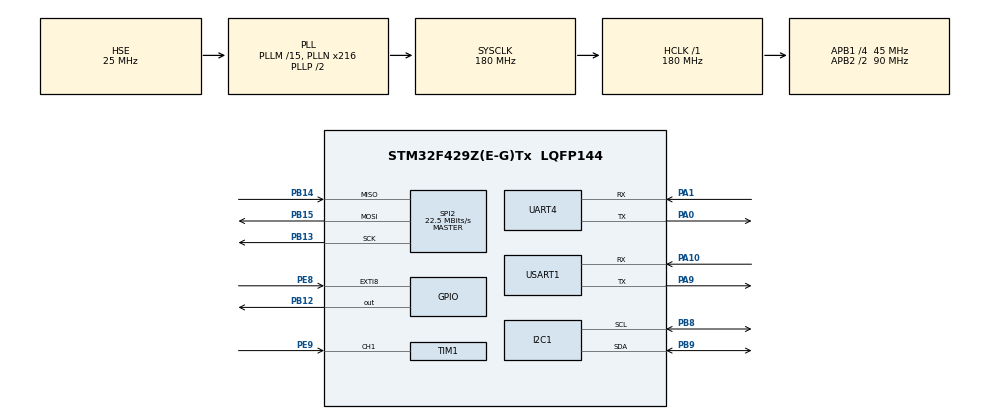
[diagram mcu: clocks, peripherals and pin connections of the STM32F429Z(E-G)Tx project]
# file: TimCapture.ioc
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I2C1.I2C_Mode=I2C_Fast
Mcu.Family=STM32F4
Mcu.Name=STM32F429Z(E-G)Tx
Mcu.Package=LQFP144
NVIC.EXTI9_5_IRQn=true\:0\:0\:false\:false\:true\:true\:true\:true
NVIC.PriorityGroup=NVIC_PRIORITYGROUP_4
NVIC.TIM1_CC_IRQn=true\:0\:0\:false\:false\:true\:true\:true\:true
NVIC.TIM1_UP_TIM10_IRQn=true\:0\:0\:false\:false\:true\:true\:true\:true
NVIC.TIM6_DAC_IRQn=true\:2\:0\:true\:false\:true\:true\:true\:true
NVIC.UART4_IRQn=true\:1\:0\:true\:false\:true\:true\:true\:true
NVIC.USART1_IRQn=true\:1\:0\:true\:false\:true\:true\:true\:true
PA0/WKUP.Mode=Asynchronous
PA0/WKUP.Signal=UART4_TX
PA1.Mode=Asynchronous
PA1.Signal=UART4_RX
PA10.Mode=Asynchronous
PA10.Signal=USART1_RX
PA13.Mode=Serial_Wire
PA13.Signal=SYS_JTMS-SWDIO
PA14.Mode=Serial_Wire
PA14.Signal=SYS_JTCK-SWCLK
PA9.Mode=Asynchronous
PA9.Signal=USART1_TX
PB12.GPIO_Speed=GPIO_SPEED_FREQ_HIGH
PB12.PinState=GPIO_PIN_SET
PB12.Signal=GPIO_Output
PB13.Mode=Full_Duplex_Master
PB13.Signal=SPI2_SCK
PB14.Mode=Full_Duplex_Master
PB14.Signal=SPI2_MISO
PB15.Mode=Full_Duplex_Master
PB15.Signal=SPI2_MOSI
PB8.Mode=I2C
PB8.Signal=I2C1_SCL
PB9.Mode=I2C
PB9.Signal=I2C1_SDA
PE8.GPIO_ModeDefaultEXTI=GPIO_MODE_IT_FALLING
PE8.GPIO_PuPd=GPIO_PULLUP
PE8.Signal=GPXTI8
PE9.Signal=S_TIM1_CH1
PH0/OSC_IN.Mode=HSE-External-Oscillator
PH0/OSC_IN.Signal=RCC_OSC_IN
PH1/OSC_OUT.Mode=HSE-External-Oscillator
PH1/OSC_OUT.Signal=RCC_OSC_OUT
ProjectManager.HeapSize=0x200
ProjectManager.StackSize=0x400
ProjectManager.TargetToolchain=MDK-ARM V5.32
RCC.48MHZClocksFreq_Value=90000000
RCC.AHBFreq_Value=180000000
RCC.APB1CLKDivider=RCC_HCLK_DIV4
RCC.APB1Freq_Value=45000000
RCC.APB1TimFreq_Value=90000000
RCC.APB2CLKDivider=RCC_HCLK_DIV2
RCC.APB2Freq_Value=90000000
RCC.APB2TimFreq_Value=180000000
RCC.CortexFreq_Value=180000000
RCC.HCLKFreq_Value=180000000
RCC.HSE_VALUE=25000000
RCC.HSI_VALUE=16000000
RCC.LSE_VALUE=32768
RCC.PLLM=15
RCC.PLLN=216
RCC.PLLSourceVirtual=RCC_PLLSOURCE_HSE
RCC.SYSCLKFreq_VALUE=180000000
RCC.SYSCLKSource=RCC_SYSCLKSOURCE_PLLCLK
RCC.VCOOutputFreq_Value=360000000
SH.S_TIM1_CH1.0=TIM1_CH1,Input_Capture1_from_TI1
SPI2.CalculateBaudRate=22.5 MBits/s
SPI2.Direction=SPI_DIRECTION_2LINES
SPI2.Mode=SPI_MODE_MASTER
SPI2.VirtualType=VM_MASTER
TIM1.AutoReloadPreload=TIM_AUTORELOAD_PRELOAD_ENABLE
TIM1.Channel-Input_Capture1_from_TI1=TIM_CHANNEL_1
TIM1.Channel-Input_Capture2_from_TI1_63=TIM_CHANNEL_2
TIM1.ICFilter_CH1=8
TIM1.ICPolarity_CH1=TIM_INPUTCHANNELPOLARITY_FALLING
TIM1.ICPrescaler-Input_Capture1_from_TI1=TIM_ICPSC_DIV1
TIM1.ICPrescaler-Input_Capture2_from_TI1_63=TIM_ICPSC_DIV1
TIM1.Period=1000-1
TIM1.Prescaler=180-1
TIM1.TIM_MasterOutputTrigger=TIM_TRGO_UPDATE
TIM6.Period=1000-1
TIM6.Prescaler=90-1
TIM6.TIM_MasterOutputTrigger=TIM_TRGO_UPDATE
UART4.VirtualMode=Asynchronous
USART1.VirtualMode=VM_ASYNC
VP_TIM1_VS_ClockSourceINT.Mode=Internal
VP_TIM1_VS_indirect_ch1.Mode=Input_Capture2_from_TI1_63
VP_TIM6_VS_ClockSourceINT.Mode=Enable_Timer
board=custom

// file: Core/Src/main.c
/* USER CODE BEGIN Header */
/**
  ******************************************************************************
  * @file           : main.c
  * @brief          : Main program body
  ******************************************************************************
  * @attention
  *
  * Copyright (c) 2025 STMicroelectronics.
  * All rights reserved.
  *
  * This software is licensed under terms that can be found in the LICENSE file
  * in the root directory of this software component.
  * If no LICENSE file comes with this software, it is provided AS-IS.
  *
  ******************************************************************************
  */
/* USER CODE END Header */
#include "main.h"
#include "i2c.h"
#include "spi.h"
#include "tim.h"
#include "usart.h"
#include "gpio.h"

/* USER CODE BEGIN Includes */
#include "stdio.h"
#include "oled.h"
#include "TimCapture.h"
#include "GD25Q40E.h"
#include "OTA_UpdateCheck.h"
/* USER CODE END Includes */

void SystemClock_Config(void);

int main(void)
{

  /* USER CODE BEGIN 1 */
	SCB->VTOR = FLASH_BASE | 0xC000;
  /* USER CODE END 1 */

  /* MCU Configuration--------------------------------------------------------*/

  /* Reset of all peripherals, Initializes the Flash interface and the Systick. */
  HAL_Init();

  /* Configure the system clock */
  SystemClock_Config();

  /* Initialize all configured peripherals */
  MX_GPIO_Init();
  MX_I2C1_Init();
  MX_TIM1_Init();
  MX_SPI2_Init();
  MX_TIM6_Init();
  MX_USART1_UART_Init();
  MX_UART4_Init();
  /* USER CODE BEGIN 2 */
	GD25Q40E_Init(&hgd1,GPIOB,GPIO_PIN_12,&hspi2);
	tim1_init();
	OLED_Init();

  /* USER CODE END 2 */

  /* Infinite loop */
  /* USER CODE BEGIN WHILE */
	char info[50] = {0};
  while (1)
  {
    /* USER CODE END WHILE */

    /* USER CODE BEGIN 3 */

		sprintf(info,"click:%d", \
		Key_Event.click);
		OLED_ShowStr(0,1,info,8);
		OTA_UpdateCheck(&OTA_Info);
  }
  /* USER CODE END 3 */
}

void SystemClock_Config(void)
{
  RCC_OscInitTypeDef RCC_OscInitStruct = {0};
  RCC_ClkInitTypeDef RCC_ClkInitStruct = {0};

  /** Configure the main internal regulator output voltage
  */
  __HAL_RCC_PWR_CLK_ENABLE();
  __HAL_PWR_VOLTAGESCALING_CONFIG(PWR_REGULATOR_VOLTAGE_SCALE1);

  /** Initializes the RCC Oscillators according to the specified parameters
  * in the RCC_OscInitTypeDef structure.
  */
  RCC_OscInitStruct.OscillatorType = RCC_OSCILLATORTYPE_HSE;
  RCC_OscInitStruct.HSEState = RCC_HSE_ON;
  RCC_OscInitStruct.PLL.PLLState = RCC_PLL_ON;
  RCC_OscInitStruct.PLL.PLLSource = RCC_PLLSOURCE_HSE;
  RCC_OscInitStruct.PLL.PLLM = 15;
  RCC_OscInitStruct.PLL.PLLN = 216;
  RCC_OscInitStruct.PLL.PLLP = RCC_PLLP_DIV2;
  RCC_OscInitStruct.PLL.PLLQ = 4;
  if (HAL_RCC_OscConfig(&RCC_OscInitStruct) != HAL_OK)
  {
    Error_Handler();
  }

  /** Activate the Over-Drive mode
  */
  if (HAL_PWREx_EnableOverDrive() != HAL_OK)
  {
    Error_Handler();
  }

  /** Initializes the CPU, AHB and APB buses clocks
  */
  RCC_ClkInitStruct.ClockType = RCC_CLOCKTYPE_HCLK|RCC_CLOCKTYPE_SYSCLK
                              |RCC_CLOCKTYPE_PCLK1|RCC_CLOCKTYPE_PCLK2;
  RCC_ClkInitStruct.SYSCLKSource = RCC_SYSCLKSOURCE_PLLCLK;
  RCC_ClkInitStruct.AHBCLKDivider = RCC_SYSCLK_DIV1;
  RCC_ClkInitStruct.APB1CLKDivider = RCC_HCLK_DIV4;
  RCC_ClkInitStruct.APB2CLKDivider = RCC_HCLK_DIV2;

  if (HAL_RCC_ClockConfig(&RCC_ClkInitStruct, FLASH_LATENCY_5) != HAL_OK)
  {
    Error_Handler();
  }
}

void Error_Handler(void)
{
  __disable_irq();
  while (1)
  {
  }
}
